# PIC32MX340F256H register map
Vendor: Microchip
Registers are 32-bit, read-write, reset 0x0 unless marked. A register's access mark holds for its fields unless they carry their own. Addresses are absolute, and some are shared; only a register's first bit layout is shown; [hi:lo] are bit positions.

## OCMP4
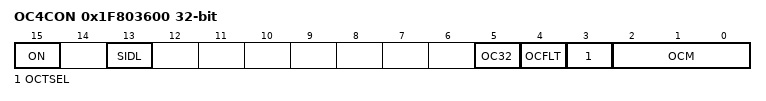
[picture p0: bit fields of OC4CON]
0x1F803600 OC4CON
  [15] ON, [13] SIDL, [5] OC32, [4] OCFLT ro, [3] OCTSEL, [2:0] OCM
0x1F803610 OC4R reset not defined — (power-on value xxxxxxxxxxxxxxxxxxxxxxxxxxxxxxxx)
0x1F803620 OC4RS reset not defined — (power-on value xxxxxxxxxxxxxxxxxxxxxxxxxxxxxxxx)

## OCMP5
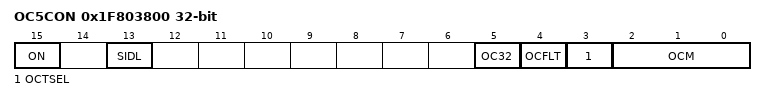
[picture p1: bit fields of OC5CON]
0x1F803800 OC5CON
  [15] ON, [13] SIDL, [5] OC32, [4] OCFLT ro, [3] OCTSEL, [2:0] OCM
0x1F803810 OC5R reset not defined — (power-on value xxxxxxxxxxxxxxxxxxxxxxxxxxxxxxxx)
0x1F803820 OC5RS reset not defined — (power-on value xxxxxxxxxxxxxxxxxxxxxxxxxxxxxxxx)

## I2C1
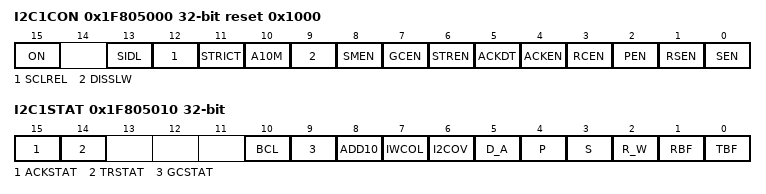
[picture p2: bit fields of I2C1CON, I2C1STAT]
0x1F805000 I2C1CON reset 0x1000
  [15] ON, [13] SIDL, [12] SCLREL, [11] STRICT, [10] A10M, [9] DISSLW, [8] SMEN, [7] GCEN, [6] STREN, [5] ACKDT, [4] ACKEN, [3] RCEN, [2] PEN, [1] RSEN, [0] SEN
0x1F805010 I2C1STAT
  [15] ACKSTAT ro
  [14] TRSTAT ro
  [10] BCL — (can only be cleared)
  [9] GCSTAT ro
  [8] ADD10 ro
  [7] IWCOL — (can only be cleared)
  [6] I2COV — (can only be cleared)
  [5] D_A ro
  [4] P — (can only be cleared)
  [3] S — (can only be cleared)
  [2] R_W ro
  [1] RBF ro
  [0] TBF ro
0x1F805020 I2C1ADD
  [9:0] I2CADD
0x1F805030 I2C1MSK
  [9:0] I2CMSK
0x1F805040 I2C1BRG
  [11:0] I2CBRG
0x1F805050 I2C1TRN
  [7:0] I2CTRN
0x1F805060 I2C1RCV
  [7:0] I2CRCV

## I2C2
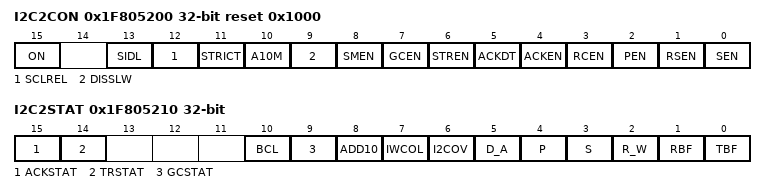
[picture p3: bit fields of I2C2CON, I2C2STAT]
0x1F805200 I2C2CON reset 0x1000
  [15] ON, [13] SIDL, [12] SCLREL, [11] STRICT, [10] A10M, [9] DISSLW, [8] SMEN, [7] GCEN, [6] STREN, [5] ACKDT, [4] ACKEN, [3] RCEN, [2] PEN, [1] RSEN, [0] SEN
0x1F805210 I2C2STAT
  [15] ACKSTAT ro
  [14] TRSTAT ro
  [10] BCL — (can only be cleared)
  [9] GCSTAT ro
  [8] ADD10 ro
  [7] IWCOL — (can only be cleared)
  [6] I2COV — (can only be cleared)
  [5] D_A ro
  [4] P — (can only be cleared)
  [3] S — (can only be cleared)
  [2] R_W ro
  [1] RBF ro
  [0] TBF ro
0x1F805220 I2C2ADD
  [9:0] I2CADD
0x1F805230 I2C2MSK
  [9:0] I2CMSK
0x1F805240 I2C2BRG
  [11:0] I2CBRG
0x1F805250 I2C2TRN
  [7:0] I2CTRN
0x1F805260 I2C2RCV
  [7:0] I2CRCV

## SPI1
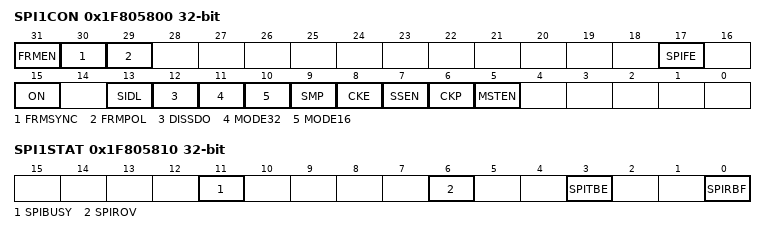
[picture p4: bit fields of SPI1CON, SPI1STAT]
0x1F805800 SPI1CON
  [31] FRMEN, [30] FRMSYNC, [29] FRMPOL, [17] SPIFE, [15] ON, [13] SIDL, [12] DISSDO, [11] MODE32, [10] MODE16, [9] SMP, [8] CKE, [7] SSEN, [6] CKP, [5] MSTEN
0x1F805810 SPI1STAT ro
  [11] SPIBUSY, [6] SPIROV, [3] SPITBE, [0] SPIRBF
0x1F805820 SPI1BUF reset not defined — (power-on value xxxxxxxxxxxxxxxxxxxxxxxxxxxxxxxx)
0x1F805830 SPI1BRG
  [8:0] SPI1BRG

## SPI2
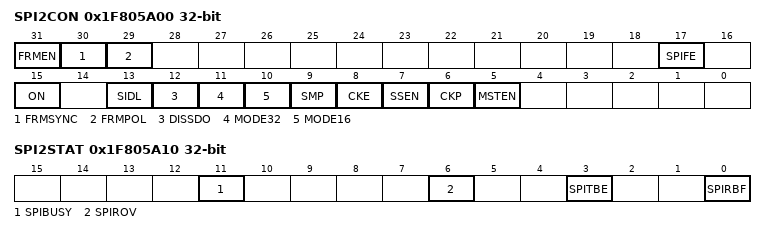
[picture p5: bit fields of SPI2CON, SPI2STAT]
0x1F805A00 SPI2CON
  [31] FRMEN, [30] FRMSYNC, [29] FRMPOL, [17] SPIFE, [15] ON, [13] SIDL, [12] DISSDO, [11] MODE32, [10] MODE16, [9] SMP, [8] CKE, [7] SSEN, [6] CKP, [5] MSTEN
0x1F805A10 SPI2STAT ro
  [11] SPIBUSY, [6] SPIROV, [3] SPITBE, [0] SPIRBF
0x1F805A20 SPI2BUF reset not defined — (power-on value xxxxxxxxxxxxxxxxxxxxxxxxxxxxxxxx)
0x1F805A30 SPI2BRG
  [8:0] SPI2BRG

## UART1
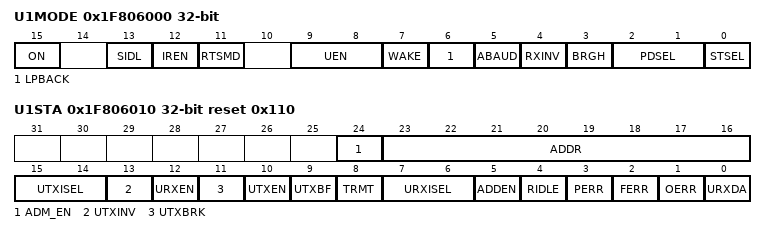
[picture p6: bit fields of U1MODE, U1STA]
0x1F806000 U1MODE
  [15] ON, [13] SIDL, [12] IREN, [11] RTSMD, [9:8] UEN, [7] WAKE, [6] LPBACK, [5] ABAUD, [4] RXINV, [3] BRGH, [2:1] PDSEL, [0] STSEL
0x1F806010 U1STA reset 0x110
  [24] ADM_EN
  [23:16] ADDR
  [15:14] UTXISEL
  [13] UTXINV
  [12] URXEN
  [11] UTXBRK
  [10] UTXEN
  [9] UTXBF ro
  [8] TRMT ro
  [7:6] URXISEL
  [5] ADDEN
  [4] RIDLE ro
  [3] PERR ro
  [2] FERR ro
  [1] OERR — (can only be cleared)
  [0] URXDA ro
0x1F806020 U1TXREG reset not defined — (power-on value -----------------------xxxxxxxxx)
  [8:0] U1TXREG
0x1F806030 U1RXREG ro
  [8:0] U1RXREG
0x1F806040 U1BRG
  [15:0] BRG

## UART2
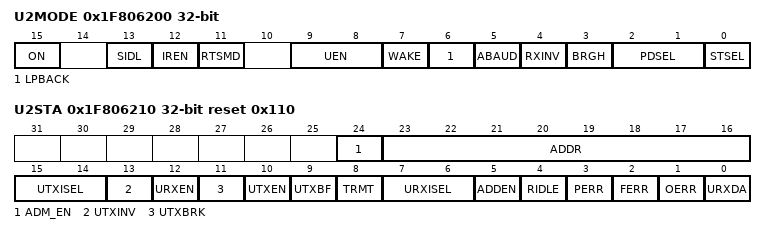
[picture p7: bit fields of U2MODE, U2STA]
0x1F806200 U2MODE
  [15] ON, [13] SIDL, [12] IREN, [11] RTSMD, [9:8] UEN, [7] WAKE, [6] LPBACK, [5] ABAUD, [4] RXINV, [3] BRGH, [2:1] PDSEL, [0] STSEL
0x1F806210 U2STA reset 0x110
  [24] ADM_EN
  [23:16] ADDR
  [15:14] UTXISEL
  [13] UTXINV
  [12] URXEN
  [11] UTXBRK
  [10] UTXEN
  [9] UTXBF ro
  [8] TRMT ro
  [7:6] URXISEL
  [5] ADDEN
  [4] RIDLE ro
  [3] PERR ro
  [2] FERR ro
  [1] OERR — (can only be cleared)
  [0] URXDA ro
0x1F806220 U2TXREG reset not defined — (power-on value -----------------------xxxxxxxxx)
  [8:0] U2TXREG
0x1F806230 U2RXREG ro
  [8:0] U2RXREG
0x1F806240 U2BRG
  [15:0] BRG
